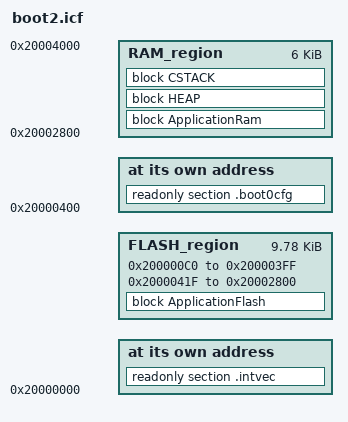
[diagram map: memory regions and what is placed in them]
/*
 * Copyright (c) 2018 zhtlab
 *
 * Permission is hereby granted, free of charge, to any person obtaining
 * a copy of this software and associated documentation files
 * (the "Software"), to deal in the Software without restriction, including
 * without limitation the rights to use, copy, modify, merge, publish,
 * distribute, sublicense, and/or sell copies of the Software, and to permit
 * persons to whom the Software is furnished to do so, subject to
 * the following conditions:
 *
 * The above copyright notice and this permission notice shall be included
 * in all copies or substantial portions of the Software.
 *
 * THE SOFTWARE IS PROVIDED "AS IS", WITHOUT WARRANTY OF ANY KIND, EXPRESS OR
 * IMPLIED, INCLUDING BUT NOT LIMITED TO THE WARRANTIES OF MERCHANTABILITY,
 * FITNESS FOR A PARTICULAR PURPOSE AND NONINFRINGEMENT. IN NO EVENT SHALL THE
 * AUTHORS OR COPYRIGHT HOLDERS BE LIABLE FOR ANY CLAIM, DAMAGES OR OTHER
 * LIABILITY, WHETHER IN AN ACTION OF CONTRACT, TORT OR OTHERWISE, ARISING
 * FROM, OUT OF OR IN CONNECTION WITH THE SOFTWARE OR THE USE OR OTHER
 * DEALINGS IN THE SOFTWARE.
 */

/*
 * icf file for boot2
 */

/*** basic definitions ****************************/
define symbol	__region_flash_start__	= 0x20000000;
define symbol	__region_flash_end__	= 0x20002800;
define symbol	__region_ram_start__	= 0x20002800;
define symbol	__region_ram_end__	= 0x20004000;

/*** each sections ********************************/
define symbol	__intvec_start__	= __region_flash_start__;
define symbol	__boot0cfg_start__	= __region_flash_start__ + 0x400;

/*** section size *********************************/
define memory mem with size = 4G;
define symbol	__size_cstack__		= (1*4096);
define symbol	__size_heap__		= (0*1024);

/*** pointers  ************************************/

define exported symbol	__VECTOR_TABLE	= __region_flash_start__;
define exported symbol	__VECTOR_RAM	= __region_ram_start__;



define region FLASH_region = mem:[from (__region_flash_start__+0xc0) to (__region_flash_start__+0x3ff)] | mem:[from (__region_flash_start__+0x41f) to __region_flash_end__];
define region RAM_region   = mem:[from __region_ram_start__   to __region_ram_end__];

define block CSTACK    with alignment = 8, size = __size_cstack__   { };
define block HEAP      with alignment = 8, size = __size_heap__     { };

/*
initialize manually { readwrite };
initialize manually { section .data};
initialize manually { section .textrw };
*/
initialize by copy { readwrite, section .textrw };
do not initialize  { section .noinit };

define block ApplicationFlash { readonly };
define block ApplicationRam { readwrite, zi};
place in FLASH_region { block ApplicationFlash };
place in RAM_region   { block ApplicationRam };
place in RAM_region   { block HEAP };
place in RAM_region   { block CSTACK };
place at address mem:__intvec_start__ { readonly section .intvec };
place at address mem:__boot0cfg_start__ { readonly section .boot0cfg };
